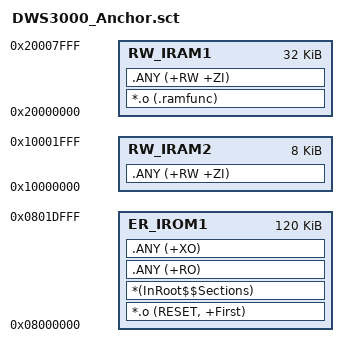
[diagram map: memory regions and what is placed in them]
; *************************************************************
; *** Scatter-Loading Description File for STM32L412KBU6    ***
; *** Flash: 128KB @ 0x08000000                             ***
; *** SRAM1:  32KB @ 0x20000000                             ***
; *** SRAM2:   8KB @ 0x10000000                             ***
; ***                                                       ***
; *** TEMPORARY: standalone build (no bootloader).          ***
; *** Application starts at 0x08000000 — flash directly.    ***
; *** Revert to 0x08002000 when the bootloader is restored. ***
; *************************************************************

LR_IROM1 0x08000000 0x0001E000  {    ; standalone build, no bootloader
  ER_IROM1 0x08000000 0x0001E000  {  ; all code
    *.o (RESET, +First)
    *(InRoot$$Sections)
    .ANY (+RO)
    .ANY (+XO)
  }
  RW_IRAM1 0x20000000 0x00008000  {  ; 32KB SRAM1
    *.o (.ramfunc)  ; RAM functions
    .ANY (+RW +ZI)
  }
  RW_IRAM2 0x10000000 0x00002000  {  ; 8KB SRAM2
    .ANY (+RW +ZI)
  }
}
